# S32K312_M7 register map
Vendor: NXP Semiconductors; File version: 1.4
CPU: CM7 r0p1, little endian, MPU, FPU, VTOR, 4 interrupt priority bits
Registers are 32-bit, read-write, reset 0x0 unless marked. A register's access mark holds for its fields unless they carry their own. Offsets are from the block's base; [hi:lo] are bit positions; {n}, {i} and the like mark numbered series.

## MU_0__MUB — MUB
Base 0x4038C000
Same registers: MU_1__MUB 0x40390000
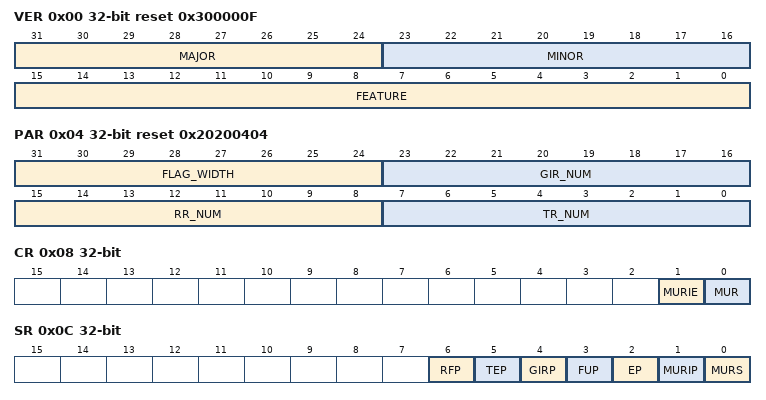
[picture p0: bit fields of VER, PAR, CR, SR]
0x00 VER ro reset 0x300000F — Version ID Register
  [31:24] MAJOR — Major Version Number
  [23:16] MINOR — Minor Version Number
  [15:0] FEATURE — Feature Set Number
0x04 PAR ro reset 0x20200404 — Parameter Register
  [31:24] FLAG_WIDTH
  [23:16] GIR_NUM — General Interrupt Request Number
  [15:8] RR_NUM — RR Number
  [7:0] TR_NUM — Transmit Register Number
0x08 CR — Control Register
  [1] MURIE — MUB Reset Interrupt Enable
    0=zero (Disables Processor B-side MU Reset Interrupt request due to MU reset issued by MUA.); 1=one (Enables Processor B-side MU Reset Interrupt request due to MU reset issued by MUA.)
  [0] MUR — MU Reset
    0=zero (Self clearing bit.); 1=one (Asserts the MU reset.)
0x0C SR (reset mask 0xFFFFFFFE) — Status Register
  [6] RFP ro — MUB Receive Full Pending Flag
    0=zero (No TRn register is written by MUA.); 1=one (Any TRn register is written by MUA.)
  [5] TEP ro — MUB Transmit Empty Pending
    0=zero (RRn register is not read by MUA.); 1=one (Any RRn register is read by MUA.)
  [4] GIRP ro — MUB General Interrupt Pending
    0=zero (No general interrupt request is sent from MUA.); 1=one (Any general interrupt request is sent from MUA.)
  [3] FUP ro — MUB Flags Update Pending
    0=zero (No pending update flags(initiated by MUB) are in process); 1=one (Pending update flags(initiated by MUB) are in process)
  [2] EP ro — MUB Side Event Pending
    0=zero (The MUB side event is not pending.); 1=one (The MUB side event is pending.)
  [1] MURIP write-1-clears — MU Reset Interrupt Pending
    0=zero (Processor A did not issue MU reset.); 1=one (Processor A issued MU reset.)
  [0] MURS ro — MUA and MUB Reset State
    0=zero (MUA and MUB are out of reset.); 1=one (MUA or MUB is in reset state.)
0x10 CCR0 — Core Control Register 0
  [0] NMI — MUA Non-maskable Interrupt Request
    0=zero (Non-maskable interrupt is not issued to the Processor A by the Processor B.); 1=one (Non-maskable interrupt is issued to the Processor A by the Processor B.)
0x18 CSSR0 (reset mask 0xFFFFFFFE) write-1-clears — Core Sticky Status Register 0
  [0] NMIC write-1-clears — Processor B Non-Maskable-Interrupt Clear
    0=zero (Default); 1=one (Writing "1" clears the MUA_CCR0[NMI] bit.)
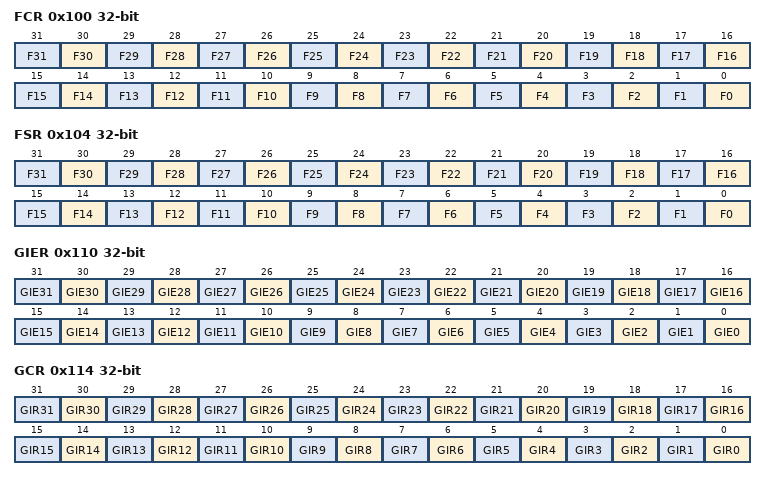
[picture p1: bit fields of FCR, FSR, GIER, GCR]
0x100 FCR — Flag Control Register
  [all] fields
    0=zero (Clears the Fn bit in the FSR register.); 1=one (Sets the Fn bit in the FSR register.)
  [n] F{n} (n=0..31) — MUB to MUA Flag n
0x104 FSR ro — Flag Status Register
  [all] fields
    0=zero (Fn bit in the MUA FCR register is written 0.); 1=one (Fn bit in the MUA FCR register is written 1.)
  [n] F{n} (n=0..31) — MUA to MUB Side Flag n
0x110 GIER — General Interrupt Enable Register
  [all] fields
    0=zero (Disables MUB General Interrupt n.); 1=one (Enables MUB General Interrupt n.)
  [n] GIE{n} (n=0..31) — MUB General Purpose Interrupt Enable n
0x114 GCR — General Control Register
  [all] fields
    0=zero (MUB General Interrupt n is not requested to the MUA.); 1=one (MUB General Interrupt n is requested to the MUA.)
  [n] GIR{n} (n=0..31) — MUB General Purpose Interrupt Request n
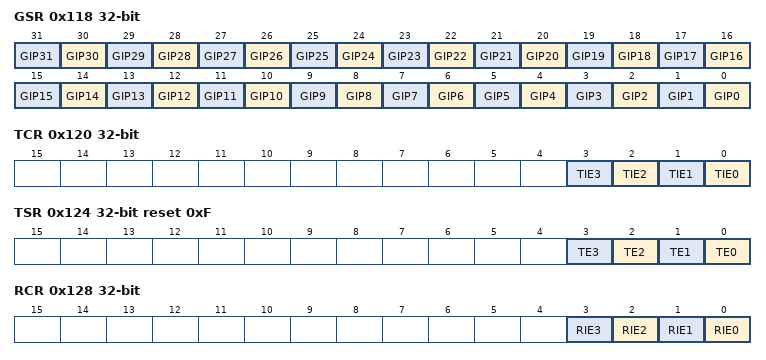
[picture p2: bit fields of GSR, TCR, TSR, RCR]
0x118 GSR write-1-clears — General Status Register
  [all] fields
    0=zero (MUB general purpose interrupt n is not pending.); 1=one (MUB general purpose interrupt n is pending.)
  [n] GIP{n} write-1-clears (n=0..31) — MUB General Interrupt Request Pending n
0x120 TCR — Transmit Control Register
  [all] fields
    0=zero (Disables MUB Transmit Interrupt n. (default)); 1=one (Enables MUB Transmit Interrupt n.)
  [n] TIE{n} (n=0..3) — MUB Transmit Interrupt Enable n
0x124 TSR ro reset 0xF — Transmit Status Register
  [all] fields
    0=zero (MUB TRn register is not empty.); 1=one (MUB TRn register is empty.)
  [n] TE{n} (n=0..3) — MUB Transmit Register n Empty
0x128 RCR — Receive Control Register
  [all] fields
    0=zero (Disables MUB Receive Interrupt n.); 1=one (Enables MUB Receive Interrupt n.)
  [n] RIE{n} (n=0..3) — MUB Receive Interrupt Enable n
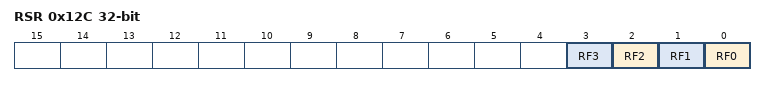
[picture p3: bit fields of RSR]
0x12C RSR ro — Receive Status Register
  [all] fields
    0=zero (MUB RRn register is not full.); 1=one (MUB RRn register has received data from MUA TRn register and is ready to be read by the MUB.)
  [n] RF{n} (n=0..3) — MUB Receive Register n Full
{0x200+4i} TR[{i}] (i=0..3) — Transmit Register
  [31:0] TR_DATA — MUB Transmit Data
{0x280+4i} RR[{i}] (i=0..3) ro — Receive Register
  [31:0] RR_DATA — MUB Receive Data
